# SWM330 register map
File version: 1.0
CPU: CM0 r1p0, little endian, 2 interrupt priority bits
Registers are 32-bit, read-write, no defined reset value unless marked. A register's access mark holds for its fields unless they carry their own. Offsets are from the block's base; [hi:lo] are bit positions; lines under a group give offsets from that group; {n}, {i} and the like mark numbered series; 'fields as' and 'values as' point back to an identical list.

## CAN0 — Registers group
Base 0x400A5000
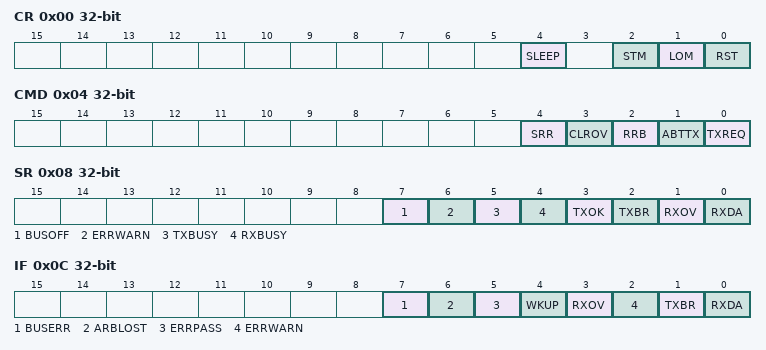
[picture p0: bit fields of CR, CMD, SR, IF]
0x00 CR
  [4] SLEEP, [2] STM, [1] LOM, [0] RST
0x04 CMD wo
  [4] SRR, [3] CLROV, [2] RRB, [1] ABTTX, [0] TXREQ
0x08 SR ro
  [7] BUSOFF, [6] ERRWARN, [5] TXBUSY, [4] RXBUSY, [3] TXOK, [2] TXBR, [1] RXOV, [0] RXDA
0x0C IF
  [7] BUSERR, [6] ARBLOST, [5] ERRPASS, [4] WKUP, [3] RXOV, [2] ERRWARN, [1] TXBR, [0] RXDA
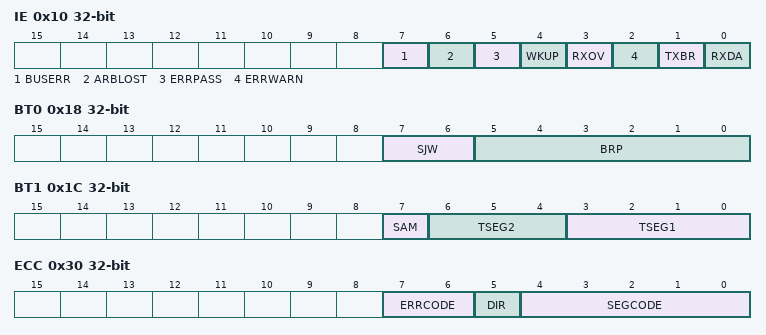
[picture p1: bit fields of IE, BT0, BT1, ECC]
0x10 IE
  fields as IF
0x14 BT2
  [3:0] BRP
0x18 BT0
  [7:6] SJW, [5:0] BRP
0x1C BT1
  [7] SAM, [6:4] TSEG2, [3:0] TSEG1
0x24 AFM
0x28 AFE
0x2C ALC ro
0x30 ECC ro
  [7:6] ERRCODE, [5] DIR, [4:0] SEGCODE
0x34 EWLIM
0x38 RXERR
0x3C TXERR
0x40 FRAME group — register cluster
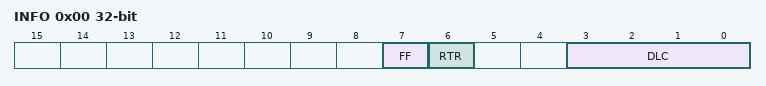
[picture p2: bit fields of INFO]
  0x00 INFO
    [7] FF, [6] RTR, [3:0] DLC
  {0x4+4j} DATA[{j}] (j=0..11)
0x74 RMCNT ro
{0x300+4i} ACR[{i}] (i=0..15)
{0x380+4i} AMR[{i}] (i=0..15)

## QSPI0 — Registers group
Base 0x78000000
Same registers: QSPI1 0x78000800
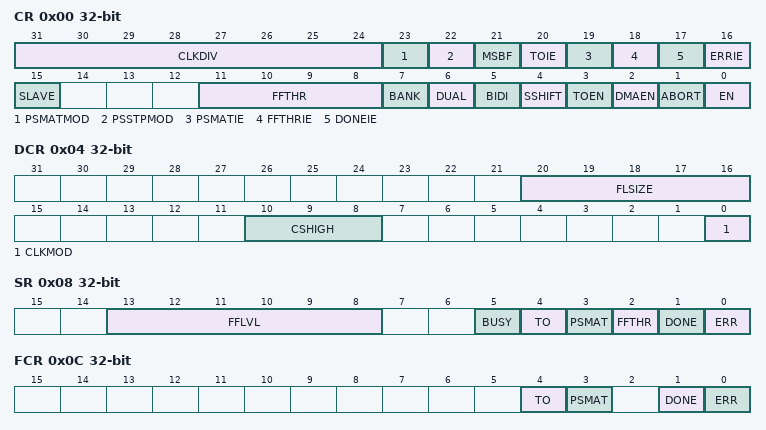
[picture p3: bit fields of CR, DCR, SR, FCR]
0x00 CR
  [31:24] CLKDIV, [23] PSMATMOD, [22] PSSTPMOD, [21] MSBF, [20] TOIE, [19] PSMATIE, [18] FFTHRIE, [17] DONEIE, [16] ERRIE, [15] SLAVE, [11:8] FFTHR, [7] BANK, [6] DUAL, [5] BIDI, [4] SSHIFT, [3] TOEN, [2] DMAEN, [1] ABORT, [0] EN
0x04 DCR
  [20:16] FLSIZE, [10:8] CSHIGH, [0] CLKMOD
0x08 SR
  [13:8] FFLVL, [5] BUSY, [4] TO, [3] PSMAT, [2] FFTHR, [1] DONE, [0] ERR
0x0C FCR
  [4] TO, [3] PSMAT, [1] DONE, [0] ERR
0x10 DLR
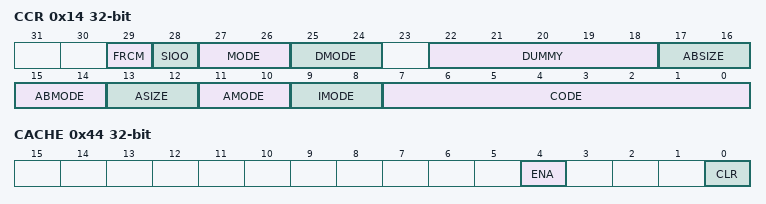
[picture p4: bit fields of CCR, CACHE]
0x14 CCR
  [29] FRCM, [28] SIOO, [27:26] MODE, [25:24] DMODE, [22:18] DUMMY, [17:16] ABSIZE, [15:14] ABMODE, [13:12] ASIZE, [11:10] AMODE, [9:8] IMODE, [7:0] CODE
0x18 AR
0x1C ABR
0x20 DRB
0x24 PSMSK
0x28 PSMAT
0x2C PSITV
0x30 CS0TO
0x40 SSHIFT
0x44 CACHE
  [4] ENA, [0] CLR

## SDIO — Registers group
Base 0x40001000
0x00 DMA_MEM_ADDR
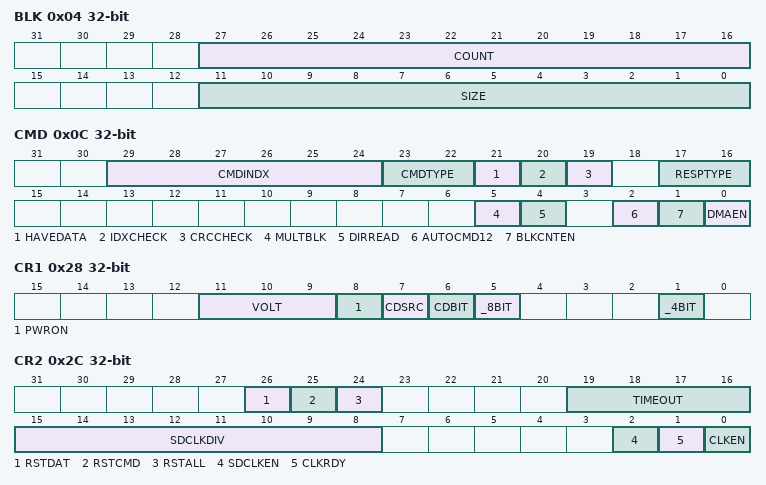
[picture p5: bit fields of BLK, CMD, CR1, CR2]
0x04 BLK
  [27:16] COUNT, [11:0] SIZE
0x08 ARG
0x0C CMD
  [29:24] CMDINDX, [23:22] CMDTYPE, [21] HAVEDATA, [20] IDXCHECK, [19] CRCCHECK, [17:16] RESPTYPE, [5] MULTBLK, [4] DIRREAD, [2] AUTOCMD12, [1] BLKCNTEN, [0] DMAEN
{0x10+4i} RESP[{i}] (i=0..3)
0x20 DATA
0x24 STAT
0x28 CR1
  [11:9] VOLT, [8] PWRON, [7] CDSRC, [6] CDBIT, [5] _8BIT, [1] _4BIT
0x2C CR2
  [26] RSTDAT, [25] RSTCMD, [24] RSTALL, [19:16] TIMEOUT, [15:8] SDCLKDIV, [2] SDCLKEN, [1] CLKRDY, [0] CLKEN
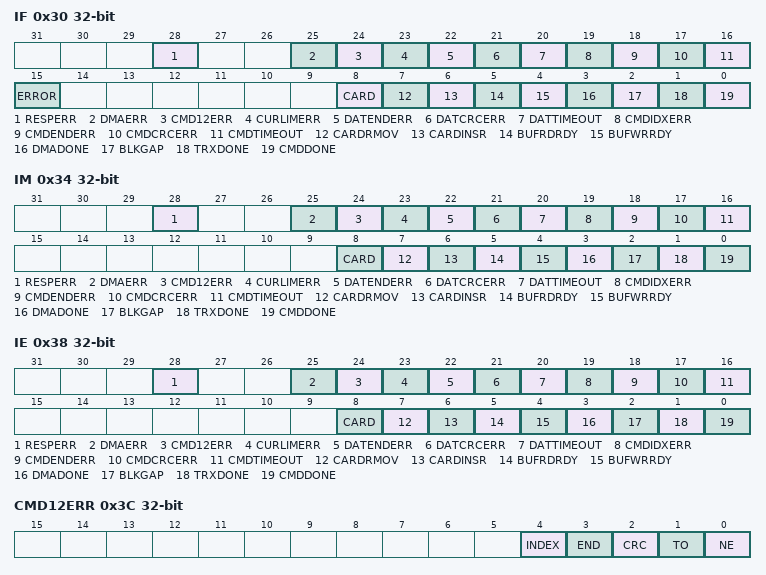
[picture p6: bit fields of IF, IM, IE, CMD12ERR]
0x30 IF
  [28] RESPERR, [25] DMAERR, [24] CMD12ERR, [23] CURLIMERR, [22] DATENDERR, [21] DATCRCERR, [20] DATTIMEOUT, [19] CMDIDXERR, [18] CMDENDERR, [17] CMDCRCERR, [16] CMDTIMEOUT, [15] ERROR, [8] CARD, [7] CARDRMOV, [6] CARDINSR, [5] BUFRDRDY, [4] BUFWRRDY, [3] DMADONE, [2] BLKGAP, [1] TRXDONE, [0] CMDDONE
0x34 IM
  [28] RESPERR, [25] DMAERR, [24] CMD12ERR, [23] CURLIMERR, [22] DATENDERR, [21] DATCRCERR, [20] DATTIMEOUT, [19] CMDIDXERR, [18] CMDENDERR, [17] CMDCRCERR, [16] CMDTIMEOUT, [8] CARD, [7] CARDRMOV, [6] CARDINSR, [5] BUFRDRDY, [4] BUFWRRDY, [3] DMADONE, [2] BLKGAP, [1] TRXDONE, [0] CMDDONE
0x38 IE
  fields as IM
0x3C CMD12ERR
  [4] INDEX, [3] END, [2] CRC, [1] TO, [0] NE

## PSRAMC — Registers group
Base 0x88000000
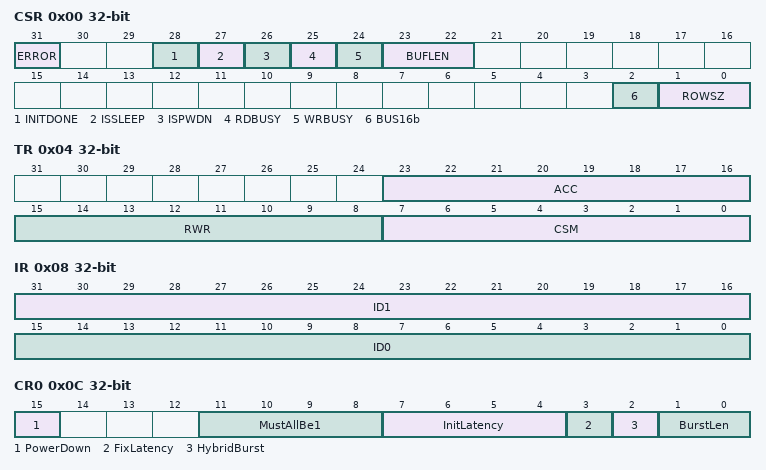
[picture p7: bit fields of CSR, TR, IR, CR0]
0x00 CSR
  [31] ERROR, [28] INITDONE, [27] ISSLEEP, [26] ISPWDN, [25] RDBUSY, [24] WRBUSY, [23:22] BUFLEN, [2] BUS16b, [1:0] ROWSZ
0x04 TR
  [23:16] ACC, [15:8] RWR, [7:0] CSM
0x08 IR ro
  [31:16] ID1, [15:0] ID0
0x0C CR0
  [15] PowerDown, [11:8] MustAllBe1, [7:4] InitLatency, [3] FixLatency, [2] HybridBurst, [1:0] BurstLen
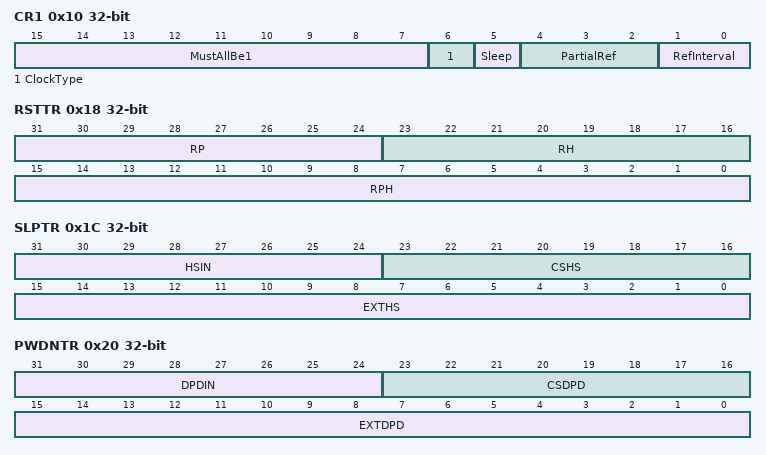
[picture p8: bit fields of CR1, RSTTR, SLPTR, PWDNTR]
0x10 CR1
  [15:7] MustAllBe1, [6] ClockType, [5] Sleep, [4:2] PartialRef, [1:0] RefInterval
0x14 INITTR
0x18 RSTTR
  [31:24] RP, [23:16] RH, [15:0] RPH
0x1C SLPTR
  [31:24] HSIN, [23:16] CSHS, [15:0] EXTHS
0x20 PWDNTR
  [31:24] DPDIN, [23:16] CSDPD, [15:0] EXTDPD
0x24 TR1US

## LCD — Registers group
Base 0x40001800
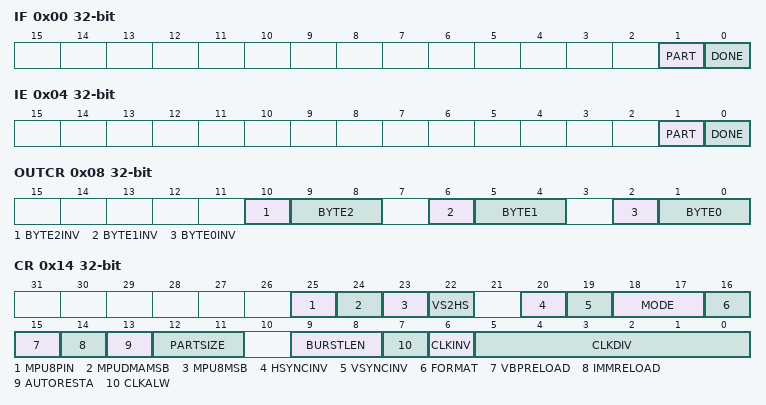
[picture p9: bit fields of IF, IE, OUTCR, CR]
0x00 IF
  [1] PART, [0] DONE
0x04 IE
  [1] PART, [0] DONE
0x08 OUTCR
  [10] BYTE2INV, [9:8] BYTE2, [6] BYTE1INV, [5:4] BYTE1, [2] BYTE0INV, [1:0] BYTE0
0x0C START
  [1] GO
0x14 CR
  [25] MPU8PIN, [24] MPUDMAMSB, [23] MPU8MSB, [22] VS2HS, [20] HSYNCINV, [19] VSYNCINV, [18:17] MODE, [16] FORMAT, [15] VBPRELOAD, [14] IMMRELOAD, [13] AUTORESTA, [12:11] PARTSIZE, [9:8] BURSTLEN, [7] CLKALW, [6] CLKINV, [5:0] CLKDIV
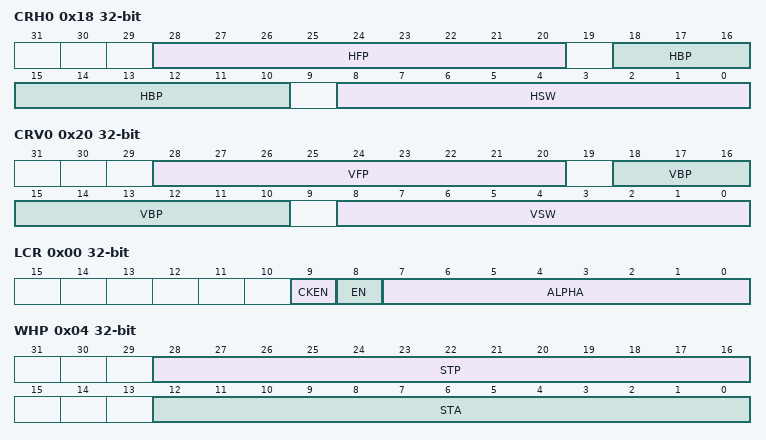
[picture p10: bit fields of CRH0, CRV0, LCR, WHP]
0x18 CRH0
  [28:20] HFP, [18:10] HBP, [8:0] HSW
0x1C CRH1
  [12:0] PIX
0x20 CRV0
  [28:20] VFP, [18:10] VBP, [8:0] VSW
0x24 CRV1
  [12:0] PIX
0x28 BGC
0x40 L0 group — register cluster
  0x00 LCR
    [9] CKEN, [8] EN, [7:0] ALPHA
  0x04 WHP
    [28:16] STP, [12:0] STA
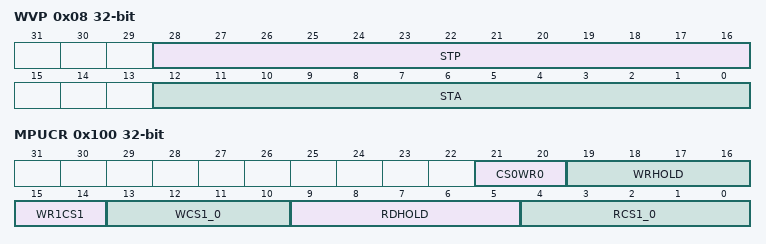
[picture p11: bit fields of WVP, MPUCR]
  0x08 WVP
    [28:16] STP, [12:0] STA
  0x0C ADDR
  0x10 LLEN
  0x14 CK
0x100 MPUCR
  [21:20] CS0WR0, [19:16] WRHOLD, [15:14] WR1CS1, [13:10] WCS1_0, [9:5] RDHOLD, [4:0] RCS1_0
